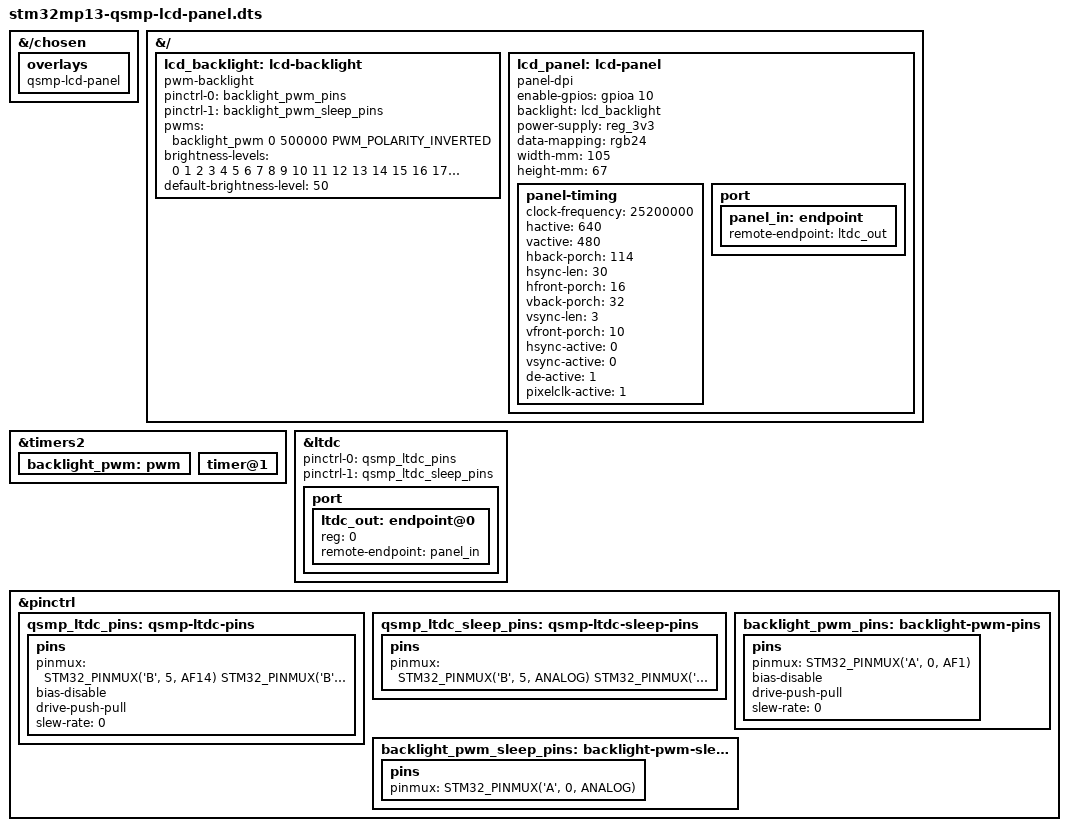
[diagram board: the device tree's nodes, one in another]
// SPDX-License-Identifier: (GPL-2.0 OR BSD-3-Clause)
/*
 * Copyright (C) 2024 Markus Bauer <MB@KARO-electronics.de>
 */

/dts-v1/;
/plugin/;

#include <dt-bindings/gpio/gpio.h>
#include <dt-bindings/pinctrl/stm32-pinfunc.h>
#include <dt-bindings/pwm/pwm.h>

&{/chosen} {
	overlays {
		qsmp-lcd-panel;
	};
};

&{/} {
	lcd_backlight: lcd-backlight {
		compatible = "pwm-backlight";
		pinctrl-names = "default", "sleep";
		pinctrl-0 = <&backlight_pwm_pins>;
		pinctrl-1 = <&backlight_pwm_sleep_pins>;
		pwms = <&backlight_pwm 0 500000 PWM_POLARITY_INVERTED>;
		brightness-levels = <0 1  2  3  4  5  6  7  8  9  10
				      11 12 13 14 15 16 17 18 19  20
				      21 22 23 24 25 26 27 28 29  30
				      31 32 33 34 35 36 37 38 39  40
				      41 42 43 44 45 46 47 48 49  50
				      51 52 53 54 55 56 57 58 59  60
				      61 62 63 64 65 66 67 68 69  70
				      71 72 73 74 75 76 77 78 79  80
				      81 82 83 84 85 86 87 88 89  90
				      91 92 93 94 95 96 97 98 99 100
				      >;
		default-brightness-level = <50>;
		status = "okay";
	};

	lcd_panel: lcd-panel {
		compatible = "panel-dpi";
		enable-gpios = <&gpioa 10 GPIO_ACTIVE_HIGH>;
		backlight = <&lcd_backlight>;
		power-supply = <&reg_3v3>;
		data-mapping = "rgb24";
		status = "okay";

		width-mm = <105>;
		height-mm = <67>;

		panel-timing {
			clock-frequency = <25200000>;
			hactive = <640>;
			vactive = <480>;
			hback-porch = <114>;
			hsync-len = <30>;
			hfront-porch = <16>;
			vback-porch = <32>;
			vsync-len = <3>;
			vfront-porch = <10>;
			hsync-active = <0>;
			vsync-active = <0>;
			de-active = <1>;
			pixelclk-active = <1>;
		};

		port {
			panel_in: endpoint {
				remote-endpoint = <&ltdc_out>;
			};
		};

		// TODO
		// insert display timings node
	};
};

&timers2 {
	/delete-property/ dmas;
	/delete-property/ dma-names;
	status = "okay";

	backlight_pwm: pwm {
		status = "okay";
	};

	timer@1 {
		status = "okay";
	};
};

&ltdc {
	pinctrl-names = "default", "sleep";
	pinctrl-0 = <&qsmp_ltdc_pins>;
	pinctrl-1 = <&qsmp_ltdc_sleep_pins>;
	status = "okay";

	port {
		#address-cells = <1>;
		#size-cells = <0>;

		ltdc_out: endpoint@0 {
			reg = <0>;
			remote-endpoint = <&panel_in>;
		};
	};
};

&pinctrl {
	qsmp_ltdc_pins: qsmp-ltdc-pins {
		pins {
			pinmux = <
				  STM32_PINMUX('B',  5, AF14) /* LCD_DE */
				  STM32_PINMUX('B', 12, AF14) /* LCD_VSYNC */
				  STM32_PINMUX('H', 10, AF13) /* LCD_HSYNC */
				  STM32_PINMUX('D',  9, AF13) /* LCD_CLK */
				  STM32_PINMUX('G',  7, AF11) /* LCD_R1 */
				  STM32_PINMUX('H',  8, AF14) /* LCD_R2 */
				  STM32_PINMUX('B', 10, AF14) /* LCD_R3 */
				  STM32_PINMUX('D', 14, AF14) /* LCD_R4 */
				  STM32_PINMUX('E',  7, AF14) /* LCD_R5 */
				  STM32_PINMUX('A',  9, AF14) /* LCD_R6 */
				  STM32_PINMUX('D', 11, AF11) /* LCD_R7 */
				  STM32_PINMUX('H', 13, AF14) /* LCD_G2 */
				  STM32_PINMUX('F',  3, AF14) /* LCD_G3 */
				  STM32_PINMUX('G',  5, AF11) /* LCD_G4 */
				  STM32_PINMUX('G',  0, AF14) /* LCD_G5 */
				  STM32_PINMUX('E', 12, AF14) /* LCD_G6 */
				  STM32_PINMUX('A', 15, AF11) /* LCD_G7 */
				  STM32_PINMUX('G',  8,  AF7) /* LCD_B1 */
				  STM32_PINMUX('D', 10, AF14) /* LCD_B2 */
				  STM32_PINMUX('F',  2, AF14) /* LCD_B3 */
				  STM32_PINMUX('H', 14, AF11) /* LCD_B4 */
				  STM32_PINMUX('D', 15, AF14) /* LCD_B5 */
				  STM32_PINMUX('B',  6,  AF7) /* LCD_B6 */
				  STM32_PINMUX('E', 15, AF14) /* LCD_B7 */
			>;
			bias-disable;
			drive-push-pull;
			slew-rate = <0>;
		};
	};

	qsmp_ltdc_sleep_pins: qsmp-ltdc-sleep-pins {
		pins {
			pinmux = <
				  STM32_PINMUX('B',  5, ANALOG) /* LCD_DE */
				  STM32_PINMUX('B', 12, ANALOG) /* LCD_VSYNC */
				  STM32_PINMUX('H', 10, ANALOG) /* LCD_HSYNC */
				  STM32_PINMUX('D',  9, ANALOG) /* LCD_CLK */
				  STM32_PINMUX('G',  7, ANALOG) /* LCD_R1 */
				  STM32_PINMUX('H',  8, ANALOG) /* LCD_R2 */
				  STM32_PINMUX('B', 10, ANALOG) /* LCD_R3 */
				  STM32_PINMUX('D', 14, ANALOG) /* LCD_R4 */
				  STM32_PINMUX('E',  7, ANALOG) /* LCD_R5 */
				  STM32_PINMUX('A',  9, ANALOG) /* LCD_R6 */
				  STM32_PINMUX('D', 11, ANALOG) /* LCD_R7 */
				  STM32_PINMUX('H', 13, ANALOG) /* LCD_G2 */
				  STM32_PINMUX('F',  3, ANALOG) /* LCD_G3 */
				  STM32_PINMUX('G',  5, ANALOG) /* LCD_G4 */
				  STM32_PINMUX('G',  0, ANALOG) /* LCD_G5 */
				  STM32_PINMUX('E', 12, ANALOG) /* LCD_G6 */
				  STM32_PINMUX('A', 15, ANALOG) /* LCD_G7 */
				  STM32_PINMUX('G',  8, ANALOG) /* LCD_B1 */
				  STM32_PINMUX('D', 10, ANALOG) /* LCD_B2 */
				  STM32_PINMUX('F',  2, ANALOG) /* LCD_B3 */
				  STM32_PINMUX('H', 14, ANALOG) /* LCD_B4 */
				  STM32_PINMUX('D', 15, ANALOG) /* LCD_B5 */
				  STM32_PINMUX('B',  6, ANALOG) /* LCD_B6 */
				  STM32_PINMUX('E', 15, ANALOG) /* LCD_B7 */
			>;
		};
	};

	backlight_pwm_pins: backlight-pwm-pins {
		pins {
			pinmux = <STM32_PINMUX('A', 0, AF1)>; /* TIM2_CH1 */
			bias-disable;
			drive-push-pull;
			slew-rate = <0>;
		};
	};

	backlight_pwm_sleep_pins: backlight-pwm-sleep-pins {
		pins {
			pinmux = <STM32_PINMUX('A', 0, ANALOG)>; /* TIM2_CH1 */
		};
	};
};
